# STM32L152 register map
File version: 1.2
CPU: CM3 r1p1, little endian, no MPU, no FPU, 4 interrupt priority bits
Registers are 32-bit, read-write, reset 0x0 unless marked. A register's access mark holds for its fields unless they carry their own. Offsets are from the block's base; [hi:lo] are bit positions; {n}, {i} and the like mark numbered series.

## TIM10 — General-purpose timers
Base 0x40010C00
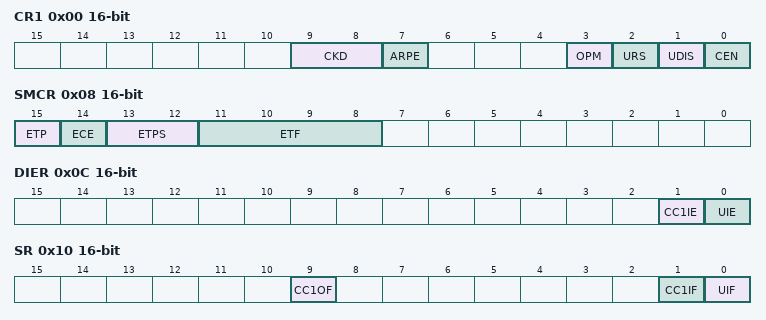
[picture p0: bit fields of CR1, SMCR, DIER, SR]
0x00 CR1 16-bit — control register 1
  [9:8] CKD — Clock division
    0=Div1 (t_DTS = t_CK_INT); 1=Div2 (t_DTS = 2 × t_CK_INT); 2=Div4 (t_DTS = 4 × t_CK_INT)
  [7] ARPE — Auto-reload preload enable
    0=Disabled (TIMx_APRR register is not buffered); 1=Enabled (TIMx_APRR register is buffered)
  [3] OPM — One-pulse mode
    0=Disabled (Counter is not stopped at update event); 1=Enabled (Counter stops counting at the next update event (clearing the CEN bit))
  [2] URS — Update request source
    0=AnyEvent (Any of counter overflow/underflow, setting UG, or update through slave mode, generates an update interrupt or DMA request); 1=CounterOnly (Only counter overflow/underflow generates an update interrupt or DMA request)
  [1] UDIS — Update disable
    0=Enabled (Update event enabled); 1=Disabled (Update event disabled)
  [0] CEN — Counter enable
    0=Disabled (Counter disabled); 1=Enabled (Counter enabled)
0x08 SMCR 16-bit — TIM10 slave mode control register
  [15] ETP — External trigger polarity
  [14] ECE — External clock enable
  [13:12] ETPS — External trigger prescaler
  [11:8] ETF — External trigger filter
0x0C DIER 16-bit — Interrupt enable register
  [n] CC{n}IE (n=1..1) — Capture/Compare {n} interrupt enable
    0=Disabled (CCx interrupt disabled); 1=Enabled (CCx interrupt enabled)
  [0] UIE — Update interrupt enable
    0=Disabled (Update interrupt disabled); 1=Enabled (Update interrupt enabled)
0x10 SR 16-bit — status register
  [n+8] CC{n}OF (n=1..1) write-0-clears — Capture/Compare {n} overcapture flag
    on read: 0=No overcapture has been detected; 1=Overcapture (The counter value has been captured in TIMx_CCRx register while CCxIF flag was already set) | on write: 0=Clear flag
  [n] CC{n}IF (n=1..1) write-0-clears — Capture/compare {n} interrupt flag
    on read: 0=NoMatch (No campture/compare has been detected); 1=Match (If CC1 is an output: The content of the counter TIMx_CNT matches the content of the TIMx_CCR1 register. If CC1 is an input: The counter value has been captured in TIMx_CCR1 register.) | on write: 0=Clear flag
  [0] UIF write-0-clears — Update interrupt flag
    on read: 0=NoUpdateOccurred; 1=UpdatePending (Update interrupt pending) | on write: 0=Clear flag
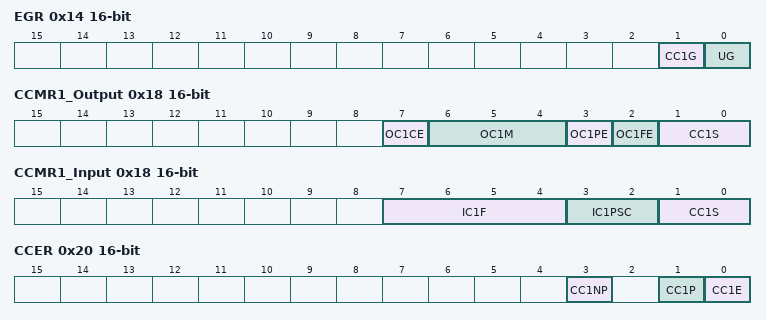
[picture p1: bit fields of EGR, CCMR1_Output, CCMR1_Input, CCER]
0x14 EGR 16-bit wo — event generation register
  [n] CC{n}G (n=1..1) — Capture/compare {n} generation
    1=Trigger (If CC1 is an output: CC1IF flag is set, Corresponding interrupt or DMA request is sent if enabled. If CC1 is an input: The current value of the counter is captured in TIMx_CCR1 register.)
  [0] UG — Update generation
    1=Update (Re-initializes the timer counter and generates an update of the registers.)
0x18 CCMR1_Output 16-bit — capture/compare mode register
  [n+6] OC{n}CE (n=1..1) — Output compare {n} clear enable
  [n+5:n+3] OC{n}M (n=1..1) — Output compare {n} mode
    0=Frozen (The comparison between the output compare register TIMx_CCRy and the counter TIMx_CNT has no effect on the outputs); 1=ActiveOnMatch (Set channel to active level on match. OCyREF signal is forced high when the counter matches the capture/compare register); 2=InactiveOnMatch (Set channel to inactive level on match. OCyREF signal is forced low when the counter matches the capture/compare register); 3=Toggle (OCyREF toggles when TIMx_CNT=TIMx_CCRy); 4=ForceInactive (OCyREF is forced low); 5=ForceActive (OCyREF is forced high); 6=PwmMode1 (In upcounting, channel is active as long as TIMx_CNT<TIMx_CCRy else inactive. In downcounting, channel is inactive as long as TIMx_CNT>TIMx_CCRy else active); 7=PwmMode2 (Inversely to PwmMode1)
  [n+2] OC{n}PE (n=1..1) — Output compare {n} preload enable
    0=Disabled (Preload register on CCRx disabled. New values written to CCRx are taken into account immediately); 1=Enabled (Preload register on CCRx enabled. Preload value is loaded into active register on each update event)
  [n+1] OC{n}FE (n=1..1) — Output compare {n} fast enable
    0=Disabled (Fast output disabled); 1=Enabled (Fast output enabled)
  [n:n-1] CC{n}S (n=1..1) — Capture/Compare {n} selection
    0=Output (CCx channel is configured as output)
0x18 CCMR1_Input 16-bit (alternate view of CCMR1_Output) — capture/compare mode register 1 (input mode)
  [n+6:n+3] IC{n}F (n=1..1) — Input capture {n} filter
    0=No filter, sampling is done at fDTS; 1=FCK_INT_N2 (fSAMPLING=fCK_INT, N=2); 2=FCK_INT_N4 (fSAMPLING=fCK_INT, N=4); 3=FCK_INT_N8 (fSAMPLING=fCK_INT, N=8); 4=FDTS_Div2_N6 (fSAMPLING=fDTS/2, N=6); 5=FDTS_Div2_N8 (fSAMPLING=fDTS/2, N=8); 6=FDTS_Div4_N6 (fSAMPLING=fDTS/4, N=6); 7=FDTS_Div4_N8 (fSAMPLING=fDTS/4, N=8); 8=FDTS_Div8_N6 (fSAMPLING=fDTS/8, N=6); 9=FDTS_Div8_N8 (fSAMPLING=fDTS/8, N=8); 10=FDTS_Div16_N5 (fSAMPLING=fDTS/16, N=5); 11=FDTS_Div16_N6 (fSAMPLING=fDTS/16, N=6); 12=FDTS_Div16_N8 (fSAMPLING=fDTS/16, N=8); 13=FDTS_Div32_N5 (fSAMPLING=fDTS/32, N=5); 14=FDTS_Div32_N6 (fSAMPLING=fDTS/32, N=6); 15=FDTS_Div32_N8 (fSAMPLING=fDTS/32, N=8)
  [n+2:n+1] IC{n}PSC (n=1..1) — Input capture {n} prescaler
    0=No prescaler, capture is done each time an edge is detected on the capture input; 1=TwoEvents (Capture is done once every 2 events); 2=FourEvents (Capture is done once every 4 events); 3=EightEvents (Capture is done once every 8 events)
  [1:0] CC1S — Capture/Compare 1 selection
    1=TI1 (CC1 channel is configured as input, IC1 is mapped on TI1)
0x20 CCER 16-bit — capture/compare enable register
  [n+2] CC{n}NP (n=1..1) — Capture/Compare {n} output Polarity
  [n] CC{n}P (n=1..1) — Capture/Compare {n} output Polarity
    0=RisingEdge (Noninverted/rising edge); 1=FallingEdge (Inverted/falling edge)
  [n-1] CC{n}E (n=1..1) — Capture/Compare {n} output enable
    0=Disabled (Capture disabled); 1=Enabled (Capture enabled)
0x24 CNT 16-bit — counter
  [15:0] CNT — TIM10 counter
0x28 PSC 16-bit — prescaler
  [15:0] PSC — TIM9 prescaler
0x2C ARR 16-bit reset 0xFFFF — auto-reload register
  [15:0] ARR — Auto-reload value
{0x32+2i} CCR{i} (i=1..1) 16-bit — capture/compare register
  [15:0] CCR — Capture/Compare value
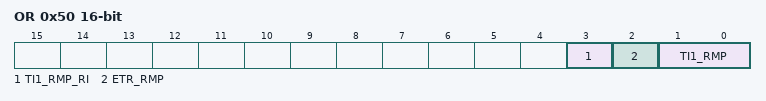
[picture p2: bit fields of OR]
0x50 OR 16-bit — option register
  [3] TI1_RMP_RI — Timer10 Input 1 remap for Routing Interface (RI)
  [2] ETR_RMP — Timer10 ETR remap
  [1:0] TI1_RMP — Timer 10 input 1 remap

## TIM11 — General-purpose timers
Base 0x40011000
Registers as TIM10; these are added or differ:
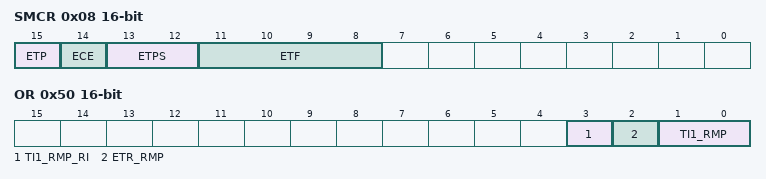
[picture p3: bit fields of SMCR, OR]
0x08 SMCR 16-bit — TIM 11 slave mode control register 1
  [15] ETP — External trigger polarity
  [14] ECE — External clock enable
  [13:12] ETPS — External trigger prescaler
  [11:8] ETF — External trigger filter
0x24 CNT 16-bit — counter
  [15:0] CNT — TIM10 counter
0x50 OR 16-bit — option register
  [3] TI1_RMP_RI — Timer11 Input 1 remap for Routing Interface (RI)
  [2] ETR_RMP — Timer11 ETR remap
  [1:0] TI1_RMP — TIM11 Input 1 remapping capability
